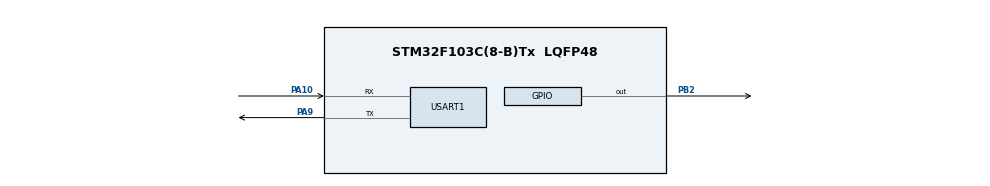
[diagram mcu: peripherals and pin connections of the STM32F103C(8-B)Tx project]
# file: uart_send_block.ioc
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Mcu.Family=STM32F1
Mcu.Name=STM32F103C(8-B)Tx
Mcu.Package=LQFP48
NVIC.PriorityGroup=NVIC_PRIORITYGROUP_4
NVIC.USART1_IRQn=true\:1\:0\:true\:false\:true\:true\:true\:true
PA10.Mode=Asynchronous
PA10.Signal=USART1_RX
PA13.Mode=Serial_Wire
PA13.Signal=SYS_JTMS-SWDIO
PA14.Mode=Serial_Wire
PA14.Signal=SYS_JTCK-SWCLK
PA9.Mode=Asynchronous
PA9.Signal=USART1_TX
PB2.Signal=GPIO_Output
ProjectManager.HeapSize=0x3000
ProjectManager.StackSize=0x1000
ProjectManager.TargetToolchain=STM32CubeIDE
RCC.APB1Freq_Value=8000000
RCC.APB2Freq_Value=8000000
USART1.VirtualMode=VM_ASYNC
board=custom

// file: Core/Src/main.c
/* USER CODE BEGIN Header */
/**Использование блокирующего HAL UART API. Вывод сообщений
В простейшем случае передачу данных микроконтроллера
по UART можно осуществить с помощью функции HAL_UART_
Transmit.

Базовое использование HAL_UART_Transmit
Приведенная программа выводит сообщения в UART c задержкой
500 мс между соседними сообщениями. Для вывода сообщений ис-
пользуется функция:
HAL_StatusTypeDef HAL_UART_Transmit(UART_HandleTypeDef
*huart, uint8_t *pData, uint16_t Size, uint32_t Timeout)
со следующим параметрами:

1) UART_HandleTypeDef *huart – указатель на структуру данных с описанием UART.
 Она генерируется CubeMX и по умолчаниюb и  называется: huart1, huart2 и т. п.;
2) uint8_t *pData – массив с данными, которые нужно передать по UART;
3) uint16_t Size – размер массива pData;
4) uint32_t Timeout – максимальное время ожидания операции. Если нужно, чтобы функция всегда ждала
завершения операции, то в качестве Timeout передается константа HAL_MAX_DELAY.
Функция HAL_UART_Transmit возвращает одно из следующих
значений:
– HAL_OK – указанное количество данных, переданное в пределах
указанного таймаута;
– код ошибки в случае ее возникновения, например: HAL_TIMEOUT
– указанное количество данных, которое не было передано в пределах указанного промежутка времени Timeout.

*/
/**
  ******************************************************************************
  * @file           : main.c
  * @brief          : Main program body
  ******************************************************************************
  * @attention
  *
  * Copyright (c) 2025 STMicroelectronics.
  * All rights reserved.
  *
  * This software is licensed under terms that can be found in the LICENSE file
  * in the root directory of this software component.
  * If no LICENSE file comes with this software, it is provided AS-IS.
  *
  ******************************************************************************
  */
/* USER CODE END Header */
#include "main.h"

/* USER CODE BEGIN Includes */
#include <string.h>
#include <stdio.h>
#include <ctype.h>
/* USER CODE END Incl */
/* USER CODE END Includes */

UART_HandleTypeDef huart1;

void SystemClock_Config(void);
static void MX_GPIO_Init(void);
static void MX_USART1_UART_Init(void);

int main(void)
{

  /* MCU Configuration--------------------------------------------------------*/

  /* Reset of all peripherals, Initializes the Flash interface and the Systick. */
  HAL_Init();

  /* Configure the system clock */
  SystemClock_Config();

  /* Initialize all configured peripherals */
  MX_GPIO_Init();
  MX_USART1_UART_Init();
  /* USER CODE BEGIN 2 */
  const size_t num_messages = 4;
  const char *messages[4] = { "-- Start --\n", "<Message 1>\n", "<Message 2>\n", "-- End --\n" };
  /* USER CODE END 2 */

  /* Infinite loop */
  /* USER CODE BEGIN WHILE */
  while (1)
  {
	  for (size_t i = 0; i < num_messages; i++) {
		  // show message
		  HAL_UART_Transmit(&huart1, (uint8_t*) messages[i], strlen(messages[i]), HAL_MAX_DELAY);
		  HAL_GPIO_TogglePin(GPIOB, GPIO_PIN_2);
		  HAL_Delay(500);
	  }
    /* USER CODE END WHILE */

  }
}

void SystemClock_Config(void)
{
  RCC_OscInitTypeDef RCC_OscInitStruct = {0};
  RCC_ClkInitTypeDef RCC_ClkInitStruct = {0};

  /** Initializes the RCC Oscillators according to the specified parameters
  * in the RCC_OscInitTypeDef structure.
  */
  RCC_OscInitStruct.OscillatorType = RCC_OSCILLATORTYPE_HSI;
  RCC_OscInitStruct.HSIState = RCC_HSI_ON;
  RCC_OscInitStruct.HSICalibrationValue = RCC_HSICALIBRATION_DEFAULT;
  RCC_OscInitStruct.PLL.PLLState = RCC_PLL_NONE;
  if (HAL_RCC_OscConfig(&RCC_OscInitStruct) != HAL_OK)
  {
    Error_Handler();
  }

  /** Initializes the CPU, AHB and APB buses clocks
  */
  RCC_ClkInitStruct.ClockType = RCC_CLOCKTYPE_HCLK|RCC_CLOCKTYPE_SYSCLK
                              |RCC_CLOCKTYPE_PCLK1|RCC_CLOCKTYPE_PCLK2;
  RCC_ClkInitStruct.SYSCLKSource = RCC_SYSCLKSOURCE_HSI;
  RCC_ClkInitStruct.AHBCLKDivider = RCC_SYSCLK_DIV1;
  RCC_ClkInitStruct.APB1CLKDivider = RCC_HCLK_DIV1;
  RCC_ClkInitStruct.APB2CLKDivider = RCC_HCLK_DIV1;

  if (HAL_RCC_ClockConfig(&RCC_ClkInitStruct, FLASH_LATENCY_0) != HAL_OK)
  {
    Error_Handler();
  }
}

static void MX_USART1_UART_Init(void)
{

  huart1.Instance = USART1;
  huart1.Init.BaudRate = 115200;
  huart1.Init.WordLength = UART_WORDLENGTH_8B;
  huart1.Init.StopBits = UART_STOPBITS_1;
  huart1.Init.Parity = UART_PARITY_NONE;
  huart1.Init.Mode = UART_MODE_TX_RX;
  huart1.Init.HwFlowCtl = UART_HWCONTROL_NONE;
  huart1.Init.OverSampling = UART_OVERSAMPLING_16;
  if (HAL_UART_Init(&huart1) != HAL_OK)
  {
    Error_Handler();
  }

}

static void MX_GPIO_Init(void)
{
  GPIO_InitTypeDef GPIO_InitStruct = {0};

  /* GPIO Ports Clock Enable */
  __HAL_RCC_GPIOB_CLK_ENABLE();
  __HAL_RCC_GPIOA_CLK_ENABLE();

  /*Configure GPIO pin Output Level */
  HAL_GPIO_WritePin(GPIOB, GPIO_PIN_2, GPIO_PIN_RESET);

  /*Configure GPIO pin : PB2 */
  GPIO_InitStruct.Pin = GPIO_PIN_2;
  GPIO_InitStruct.Mode = GPIO_MODE_OUTPUT_PP;
  GPIO_InitStruct.Pull = GPIO_NOPULL;
  GPIO_InitStruct.Speed = GPIO_SPEED_FREQ_LOW;
  HAL_GPIO_Init(GPIOB, &GPIO_InitStruct);

}

void Error_Handler(void)
{
  __disable_irq();
  while (1)
  {
  }
}
